VERSION "37805-RAD-A820-M1 PCM RECEIVE FRAMES"

NS_ :

BS_:
BU_: PCM XXX HDS INFERRED PROVEN

CM_ SG_ 212 VALIDATION_CODE "Normally 0xE";
CM_ SG_ 212 A_C_SWITCH "A/C compressor?";
CM_ SG_ 212 FUEL_LEVEL_SENSOR_VOLTAGE "Nonlinear input for EVAP.";

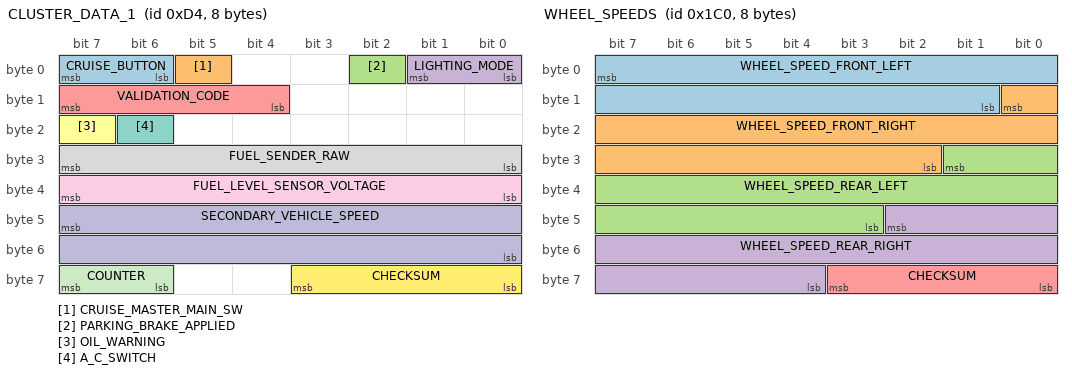
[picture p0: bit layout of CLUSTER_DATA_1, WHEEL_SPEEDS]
BO_ 212 CLUSTER_DATA_1: 8 CLUSTER
 SG_ CRUISE_BUTTON : 7|2@0+ (1,0) [0|3] "code" PCM,PROVEN
 SG_ CRUISE_MASTER_MAIN_SW : 5|1@0+ (1,0) [0|1] "bool" PCM,HDS
 SG_ PARKING_BRAKE_APPLIED : 2|1@0+ (1,0) [0|1] "bool" PCM,PROVEN
 SG_ LIGHTING_MODE : 1|2@0+ (1,0) [0|3] "code" PCM,PROVEN
 SG_ VALIDATION_CODE : 15|4@0+ (1,0) [0|15] "code" PCM,PROVEN
 SG_ OIL_WARNING : 23|1@0+ (1,0) [0|1] "bool" PCM,PROVEN
 SG_ A_C_SWITCH : 22|1@0+ (1,0) [0|1] "bool" PCM,HDS
 SG_ FUEL_SENDER_RAW : 31|8@0+ (1,0) [0|255] "raw" PCM,PROVEN
 SG_ FUEL_LEVEL_SENSOR_VOLTAGE : 39|8@0+ (4,0) [0|1020] "internal_count" PCM,HDS
 SG_ SECONDARY_VEHICLE_SPEED : 47|16@0+ (0.01,0) [0|655.35] "km/h" PCM,PROVEN
 SG_ COUNTER : 63|2@0+ (1,0) [0|3] "count" PCM,PROVEN
 SG_ CHECKSUM : 59|4@0+ (1,0) [0|15] "raw" PCM,PROVEN

VAL_ 212 CRUISE_BUTTON 0 "none" 1 "SET/DECEL" 2 "RESUME/ACCEL" 3 "CANCEL" ;
VAL_ 212 LIGHTING_MODE 0 "off" 1 "parking" 2 "low beam" 3 "high beam" ;

BO_ 448 WHEEL_SPEEDS: 8 VSA
 SG_ WHEEL_SPEED_FRONT_LEFT : 7|15@0+ (0.01,0) [0|327.67] "km/h" PCM,INFERRED
 SG_ WHEEL_SPEED_FRONT_RIGHT : 8|15@0+ (0.01,0) [0|327.67] "km/h" PCM,INFERRED
 SG_ WHEEL_SPEED_REAR_LEFT : 25|15@0+ (0.01,0) [0|327.67] "km/h" PCM,INFERRED
 SG_ WHEEL_SPEED_REAR_RIGHT : 42|15@0+ (0.01,0) [0|327.67] "km/h" PCM,INFERRED
 SG_ CHECKSUM : 59|4@0+ (1,0) [0|15] "raw" PCM,PROVEN

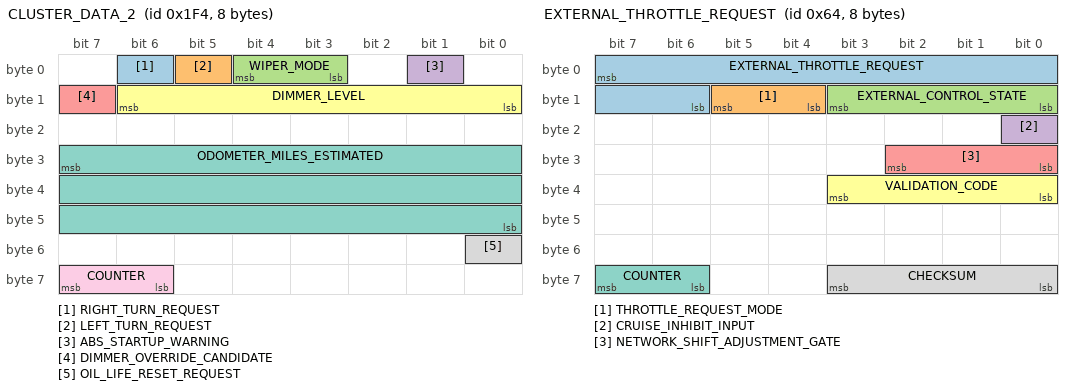
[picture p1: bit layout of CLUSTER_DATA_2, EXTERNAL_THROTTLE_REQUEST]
BO_ 500 CLUSTER_DATA_2: 8 CLUSTER
 SG_ RIGHT_TURN_REQUEST : 6|1@0+ (1,0) [0|1] "bool" PCM,PROVEN
 SG_ LEFT_TURN_REQUEST : 5|1@0+ (1,0) [0|1] "bool" PCM,PROVEN
 SG_ WIPER_MODE : 4|2@0+ (1,0) [0|3] "code" PCM,PROVEN
 SG_ ABS_STARTUP_WARNING : 1|1@0+ (1,0) [0|1] "bool" PCM,PROVEN
 SG_ DIMMER_OVERRIDE_CANDIDATE : 15|1@0+ (1,0) [0|1] "bool" PCM,INFERRED
 SG_ DIMMER_LEVEL : 14|7@0+ (1,0) [0|127] "code" PCM,INFERRED
 SG_ ODOMETER_MILES_ESTIMATED : 31|24@0+ (0.6211180124223602,0) [0|10420630.434782607] "mi" PCM,PROVEN
 SG_ OIL_LIFE_RESET_REQUEST : 48|1@0+ (1,0) [0|1] "bool" PCM,PROVEN
 SG_ COUNTER : 63|2@0+ (1,0) [0|3] "count" PCM,PROVEN

VAL_ 500 WIPER_MODE 0 "off" 1 "intermittent" 2 "low" 3 "high" ;

CM_ SG_ 100 NETWORK_SHIFT_ADJUSTMENT_GATE "Disabled in this firmware";
BO_ 100 EXTERNAL_THROTTLE_REQUEST: 8 XXX
 SG_ EXTERNAL_THROTTLE_REQUEST : 7|10@0+ (0.1,0) [0|102.3] "deg" PCM,PROVEN
 SG_ THROTTLE_REQUEST_MODE : 13|2@0+ (1,0) [0|3] "code" PCM,PROVEN
 SG_ EXTERNAL_CONTROL_STATE : 11|4@0+ (1,0) [0|15] "code" PCM,PROVEN
 SG_ CRUISE_INHIBIT_INPUT : 16|1@0+ (1,0) [0|1] "bool" PCM,PROVEN
 SG_ NETWORK_SHIFT_ADJUSTMENT_GATE : 26|3@0+ (1,0) [0|7] "code" PCM,PROVEN
 SG_ VALIDATION_CODE : 35|4@0+ (1,0) [0|15] "code" PCM,PROVEN
 SG_ COUNTER : 63|2@0+ (1,0) [0|3] "count" PCM,PROVEN
 SG_ CHECKSUM : 59|4@0+ (1,0) [0|15] "raw" PCM,PROVEN
VAL_ 100 THROTTLE_REQUEST_MODE 0 "inactive" 1 "minimum" 2 "maximum" 3 "inactive" ;

CM_ BO_ 160 "Disabled in this firmware";
CM_ SG_ 160 CRUISE_SPEED_LIMIT_ENABLE "Applies in cruise mode 0";
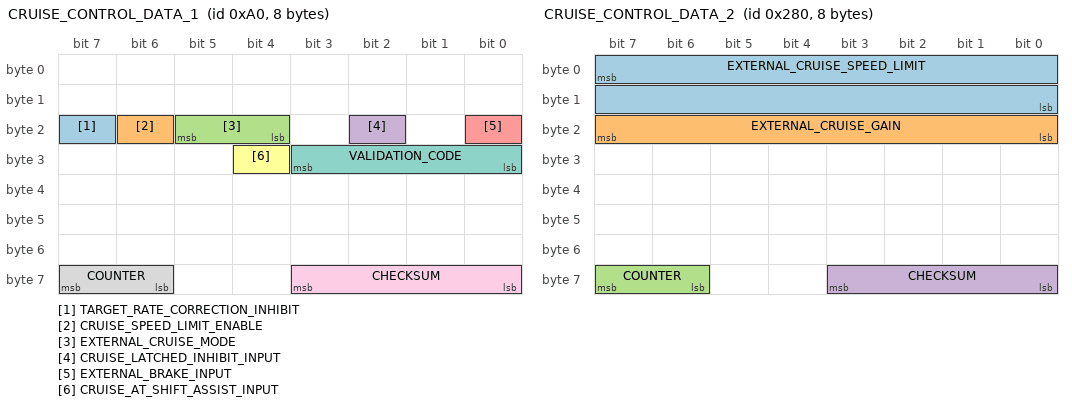
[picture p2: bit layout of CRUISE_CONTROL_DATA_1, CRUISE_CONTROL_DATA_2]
BO_ 160 CRUISE_CONTROL_DATA_1: 8 XXX
 SG_ TARGET_RATE_CORRECTION_INHIBIT : 23|1@0+ (1,0) [0|1] "bool" PCM,PROVEN
 SG_ CRUISE_SPEED_LIMIT_ENABLE : 22|1@0+ (1,0) [0|1] "bool" PCM,PROVEN
 SG_ EXTERNAL_CRUISE_MODE : 21|2@0+ (1,0) [0|3] "code" PCM,PROVEN
 SG_ CRUISE_LATCHED_INHIBIT_INPUT : 18|1@0+ (1,0) [0|1] "bool" PCM,PROVEN
 SG_ EXTERNAL_BRAKE_INPUT : 16|1@0+ (1,0) [0|1] "bool" PCM,PROVEN
 SG_ CRUISE_AT_SHIFT_ASSIST_INPUT : 28|1@0+ (1,0) [0|1] "bool" PCM,PROVEN
 SG_ VALIDATION_CODE : 27|4@0+ (1,0) [0|15] "code" PCM,PROVEN
 SG_ COUNTER : 63|2@0+ (1,0) [0|3] "count" PCM,PROVEN
 SG_ CHECKSUM : 59|4@0+ (1,0) [0|15] "raw" PCM,PROVEN
VAL_ 160 EXTERNAL_CRUISE_MODE 0 "external variant0" 1 "external variant1" 2 "ordinary cruise" 3 "invalid or fallback" ;

CM_ BO_ 640 "Disabled in this firmware";
BO_ 640 CRUISE_CONTROL_DATA_2: 8 XXX
 SG_ EXTERNAL_CRUISE_SPEED_LIMIT : 7|16@0+ (0.01,0) [0|655.35] "km/h" PCM,PROVEN
 SG_ EXTERNAL_CRUISE_GAIN : 23|8@0+ (0.005,0) [0|1.2750000000000001] "ratio" PCM,PROVEN
 SG_ COUNTER : 63|2@0+ (1,0) [0|3] "count" PCM,PROVEN
 SG_ CHECKSUM : 59|4@0+ (1,0) [0|15] "raw" PCM,PROVEN

CM_ BO_ 1065 "Disabled in this firmware";
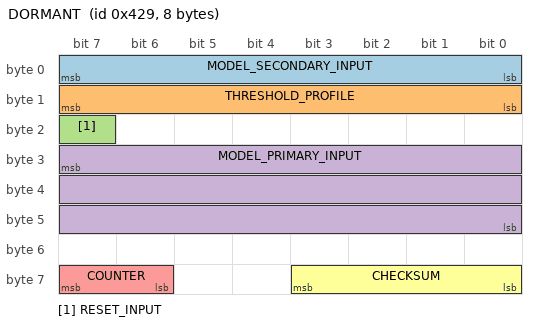
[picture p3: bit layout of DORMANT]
BO_ 1065 DORMANT: 8 XXX
 SG_ MODEL_SECONDARY_INPUT : 7|8@0+ (1,0) [0|255] "raw" PCM,PROVEN
 SG_ THRESHOLD_PROFILE : 15|8@0+ (1,0) [0|255] "code" PCM,PROVEN
 SG_ RESET_INPUT : 23|1@0+ (1,0) [0|1] "bool" PCM,PROVEN
 SG_ MODEL_PRIMARY_INPUT : 31|24@0+ (1,0) [0|16777215] "raw" PCM,PROVEN
 SG_ COUNTER : 63|2@0+ (1,0) [0|3] "count" PCM,PROVEN
 SG_ CHECKSUM : 59|4@0+ (1,0) [0|15] "raw" PCM,PROVEN
